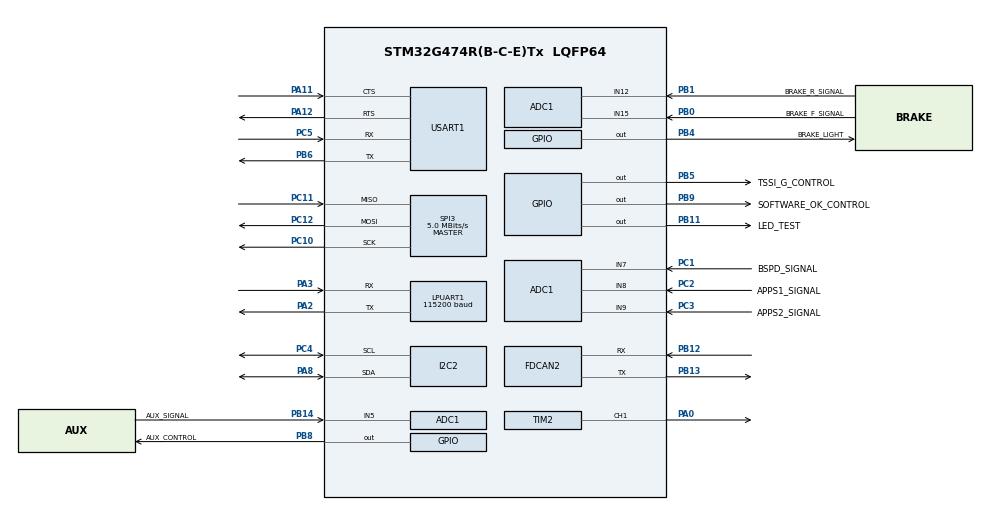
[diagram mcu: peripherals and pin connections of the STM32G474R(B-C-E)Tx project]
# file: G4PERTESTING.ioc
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ADC1.Channel-2\#ChannelRegularConversion=ADC_CHANNEL_5
ADC1.Channel-3\#ChannelRegularConversion=ADC_CHANNEL_7
ADC1.Channel-4\#ChannelRegularConversion=ADC_CHANNEL_8
ADC1.Channel-5\#ChannelRegularConversion=ADC_CHANNEL_9
ADC1.Channel-6\#ChannelRegularConversion=ADC_CHANNEL_12
ADC1.Channel-7\#ChannelRegularConversion=ADC_CHANNEL_15
ADC1.ClockPrescaler=ADC_CLOCK_ASYNC_DIV256
ADC1.ContinuousConvMode=ENABLE
ADC1.DMAContinuousRequests=ENABLE
ADC1.EOCSelection=ADC_EOC_SEQ_CONV
ADC1.ExternalTrigConv=ADC_SOFTWARE_START
ADC1.NbrOfConversion=6
ADC1.NbrOfConversionFlag=1
ADC1.OffsetNumber-2\#ChannelRegularConversion=ADC_OFFSET_NONE
ADC1.OffsetNumber-3\#ChannelRegularConversion=ADC_OFFSET_NONE
ADC1.OffsetNumber-4\#ChannelRegularConversion=ADC_OFFSET_NONE
ADC1.OffsetNumber-5\#ChannelRegularConversion=ADC_OFFSET_NONE
ADC1.OffsetNumber-6\#ChannelRegularConversion=ADC_OFFSET_NONE
ADC1.OffsetNumber-7\#ChannelRegularConversion=ADC_OFFSET_NONE
ADC1.Rank-2\#ChannelRegularConversion=1
ADC1.Rank-3\#ChannelRegularConversion=2
ADC1.Rank-4\#ChannelRegularConversion=3
ADC1.Rank-5\#ChannelRegularConversion=4
ADC1.Rank-6\#ChannelRegularConversion=5
ADC1.Rank-7\#ChannelRegularConversion=6
ADC1.SamplingTime-2\#ChannelRegularConversion=ADC_SAMPLETIME_92CYCLES_5
ADC1.SamplingTime-3\#ChannelRegularConversion=ADC_SAMPLETIME_92CYCLES_5
ADC1.SamplingTime-4\#ChannelRegularConversion=ADC_SAMPLETIME_92CYCLES_5
ADC1.SamplingTime-5\#ChannelRegularConversion=ADC_SAMPLETIME_92CYCLES_5
ADC1.SamplingTime-6\#ChannelRegularConversion=ADC_SAMPLETIME_92CYCLES_5
ADC1.SamplingTime-7\#ChannelRegularConversion=ADC_SAMPLETIME_92CYCLES_5
ADC1.master=1
Dma.ADC1.0.Direction=DMA_PERIPH_TO_MEMORY
Dma.ADC1.0.EventEnable=DISABLE
Dma.ADC1.0.Instance=DMA1_Channel1
Dma.ADC1.0.MemDataAlignment=DMA_MDATAALIGN_HALFWORD
Dma.ADC1.0.MemInc=DMA_MINC_ENABLE
Dma.ADC1.0.Mode=DMA_CIRCULAR
Dma.ADC1.0.PeriphDataAlignment=DMA_PDATAALIGN_HALFWORD
Dma.ADC1.0.PeriphInc=DMA_PINC_DISABLE
Dma.ADC1.0.Polarity=HAL_DMAMUX_REQ_GEN_RISING
Dma.ADC1.0.Priority=DMA_PRIORITY_LOW
Dma.ADC1.0.RequestNumber=1
Dma.ADC1.0.SignalID=NONE
Dma.ADC1.0.SyncEnable=DISABLE
Dma.ADC1.0.SyncPolarity=HAL_DMAMUX_SYNC_NO_EVENT
Dma.ADC1.0.SyncRequestNumber=1
Dma.ADC1.0.SyncSignalID=NONE
Dma.Request0=ADC1
FDCAN2.AutoRetransmission=ENABLE
FDCAN2.CalculateBaudRateNominal=1000000
FDCAN2.CalculateTimeBitNominal=1000
FDCAN2.CalculateTimeQuantumNominal=6.25
FDCAN2.DataPrescaler=8
FDCAN2.DataSyncJumpWidth=16
FDCAN2.DataTimeSeg1=14
FDCAN2.DataTimeSeg2=5
FDCAN2.ExtFiltersNbr=2
FDCAN2.FrameFormat=FDCAN_FRAME_CLASSIC
FDCAN2.NominalPrescaler=1
FDCAN2.NominalSyncJumpWidth=16
FDCAN2.NominalTimeSeg1=119
FDCAN2.NominalTimeSeg2=40
FDCAN2.ProtocolException=ENABLE
FDCAN2.StdFiltersNbr=0
FDCAN2.TransmitPause=DISABLE
I2C2.Timing=0x30D29DE4
LPUART1.BaudRate=115200
Mcu.Family=STM32G4
Mcu.Name=STM32G474R(B-C-E)Tx
Mcu.Package=LQFP64
NVIC.FDCAN2_IT0_IRQn=true\:0\:0\:false\:false\:true\:true\:true\:true
NVIC.PriorityGroup=NVIC_PRIORITYGROUP_4
PA0.Signal=S_TIM2_CH1
PA11.Mode=CTS_RTS
PA11.Signal=USART1_CTS
PA12.Mode=CTS_RTS
PA12.Signal=USART1_RTS
PA13.Mode=Trace_Asynchronous_SW
PA13.Signal=SYS_JTMS-SWDIO
PA14.Mode=Trace_Asynchronous_SW
PA14.Signal=SYS_JTCK-SWCLK
PA2.GPIO_Speed=GPIO_SPEED_FREQ_HIGH
PA2.Mode=Asynchronous
PA2.Signal=LPUART1_TX
PA3.GPIO_Speed=GPIO_SPEED_FREQ_HIGH
PA3.Mode=Asynchronous
PA3.Signal=LPUART1_RX
PA5.GPIO_Label=BSPD_SENSE
PA5.Signal=ADC2_IN13
PA6.GPIO_Label=IMD_SENSE
PA6.Signal=ADC2_IN3
PA7.GPIO_Label=AMS_SENSE
PA7.Signal=ADC2_IN4
PA8.Mode=I2C
PA8.Signal=I2C2_SDA
PB0.GPIO_Label=BRAKE_F_SIGNAL
PB0.Mode=IN15-Single-Ended
PB0.Signal=ADC1_IN15
PB1.GPIO_Label=BRAKE_R_SIGNAL
PB1.Mode=IN12-Single-Ended
PB1.Signal=ADC1_IN12
PB11.GPIO_Label=LED_TEST
PB11.Signal=GPIO_Output
PB12.GPIO_PuPd=GPIO_PULLUP
PB12.GPIO_Speed=GPIO_SPEED_FREQ_VERY_HIGH
PB12.Mode=FDCAN_Activate
PB12.Signal=FDCAN2_RX
PB13.GPIO_Speed=GPIO_SPEED_FREQ_VERY_HIGH
PB13.Mode=FDCAN_Activate
PB13.Signal=FDCAN2_TX
PB14.GPIO_Label=AUX_SIGNAL
PB14.Mode=IN5-Single-Ended
PB14.Signal=ADC1_IN5
PB15.GPIO_Label=STEERING_ANGLE
PB15.Signal=ADC2_IN15
PB3.Mode=Trace_Asynchronous_SW
PB3.Signal=SYS_JTDO-SWO
PB4.GPIO_Label=BRAKE_LIGHT
PB4.Signal=GPIO_Output
PB5.GPIO_Label=TSSI_G_CONTROL
PB5.Signal=GPIO_Output
PB6.Mode=Asynchronous
PB6.Signal=USART1_TX
PB7.Signal=UART4_CTS
PB8-BOOT0.GPIO_Label=AUX_CONTROL
PB8-BOOT0.Signal=GPIO_Output
PB9.GPIO_Label=SOFTWARE_OK_CONTROL
PB9.Signal=GPIO_Output
PC1.GPIO_Label=BSPD_SIGNAL
PC1.Mode=IN7-Single-Ended
PC1.Signal=ADC1_IN7
PC10.Mode=Full_Duplex_Master
PC10.Signal=SPI3_SCK
PC11.Mode=Full_Duplex_Master
PC11.Signal=SPI3_MISO
PC12.Mode=Full_Duplex_Master
PC12.Signal=SPI3_MOSI
PC2.GPIO_Label=APPS1_SIGNAL
PC2.Mode=IN8-Single-Ended
PC2.Signal=ADC1_IN8
PC3.GPIO_Label=APPS2_SIGNAL
PC3.Mode=IN9-Single-Ended
PC3.Signal=ADC1_IN9
PC4.Mode=I2C
PC4.Signal=I2C2_SCL
PC5.Mode=Asynchronous
PC5.Signal=USART1_RX
PF0-OSC_IN.Mode=HSE-External-Oscillator
PF0-OSC_IN.Signal=RCC_OSC_IN
PF1-OSC_OUT.Mode=HSE-External-Oscillator
PF1-OSC_OUT.Signal=RCC_OSC_OUT
ProjectManager.HeapSize=0x200
ProjectManager.StackSize=0x400
ProjectManager.TargetToolchain=CMake
RCC.ADC12Freq_Value=160000000
RCC.ADC345Freq_Value=160000000
RCC.AHBFreq_Value=160000000
RCC.APB1Freq_Value=160000000
RCC.APB1TimFreq_Value=160000000
RCC.APB2Freq_Value=160000000
RCC.APB2TimFreq_Value=160000000
RCC.CortexFreq_Value=160000000
RCC.EXTERNAL_CLOCK_VALUE=12288000
RCC.EnbaleCSS=true
RCC.HCLKFreq_Value=160000000
RCC.HSE_VALUE=16000000
RCC.HSI48_VALUE=48000000
RCC.HSI_VALUE=16000000
RCC.LSE_VALUE=32768
RCC.PLLN=20
RCC.PLLSourceVirtual=RCC_PLLSOURCE_HSE
RCC.SYSCLKFreq_VALUE=160000000
RCC.SYSCLKSource=RCC_SYSCLKSOURCE_PLLCLK
RCC.USBFreq_Value=160000000
RCC.VCOOutputFreq_Value=320000000
SH.S_TIM2_CH1.0=TIM2_CH1,Forced Output1 CH1
SPI3.BaudRatePrescaler=SPI_BAUDRATEPRESCALER_32
SPI3.CalculateBaudRate=5.0 MBits/s
SPI3.Direction=SPI_DIRECTION_2LINES
SPI3.Mode=SPI_MODE_MASTER
SPI3.VirtualType=VM_MASTER
TIM2.Channel-Forced\ Output1\ CH1=TIM_CHANNEL_1
USART1.VirtualMode-Asynchronous=VM_ASYNC
VP_SYS_VS_DBSignals.Mode=DisableDeadBatterySignals
VP_TIM2_VS_ClockSourceINT.Mode=Internal
board=custom

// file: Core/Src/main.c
/* USER CODE BEGIN Header */
/**
 ******************************************************************************
 * @file           : main.c
 * @brief          : Main program body
 ******************************************************************************
 * @attention
 *
 * Copyright (c) 2024 STMicroelectronics.
 * All rights reserved.
 *
 * This software is licensed under terms that can be found in the LICENSE file
 * in the root directory of this software component.
 * If no LICENSE file comes with this software, it is provided AS-IS.
 *
 ******************************************************************************
 */
/* USER CODE END Header */
#include "main.h"

#include "adc.h"
#include "dma.h"
#include "fdcan.h"
#include "gpio.h"
#include "i2c.h"
#include "spi.h"
#include "tim.h"
#include "usart.h"

void SystemClock_Config(void);

int main(void)
{

	/* MCU
	 * Configuration--------------------------------------------------------*/

	/* Reset of all peripherals, Initializes the Flash interface and the
	 * Systick. */
	HAL_Init();

	/* Configure the system clock */
	SystemClock_Config();

	/* Initialize all configured peripherals */
	MX_GPIO_Init();
	MX_DMA_Init();
	MX_FDCAN2_Init();
	MX_ADC1_Init();
	MX_LPUART1_UART_Init();
	MX_I2C2_Init();
	MX_USART1_UART_Init();
	MX_SPI3_Init();
	MX_TIM2_Init();
	/* USER CODE BEGIN 2 */

	/* Initialize CAN interface */

	/* USER CODE END 2 */

	/* Infinite loop */
	while (1) {

		// BLINKY
		HAL_GPIO_WritePin(GPIOA, GPIO_PIN_5, GPIO_PIN_SET);
		HAL_Delay(1000);
		HAL_GPIO_WritePin(GPIOA, GPIO_PIN_5, GPIO_PIN_RESET);
		HAL_Delay(1000);

		/* USER CODE BEGIN 3 */
	}
}

void SystemClock_Config(void)
{
	LL_FLASH_SetLatency(LL_FLASH_LATENCY_4);
	while (LL_FLASH_GetLatency() != LL_FLASH_LATENCY_4) {}
	LL_PWR_EnableRange1BoostMode();
	LL_RCC_HSE_Enable();
	/* Wait till HSE is ready */
	while (LL_RCC_HSE_IsReady() != 1) {}

	LL_RCC_HSE_EnableCSS();
	LL_RCC_PLL_ConfigDomain_SYS(LL_RCC_PLLSOURCE_HSE, LL_RCC_PLLM_DIV_1, 20, LL_RCC_PLLR_DIV_2);
	LL_RCC_PLL_EnableDomain_SYS();
	LL_RCC_PLL_Enable();
	/* Wait till PLL is ready */
	while (LL_RCC_PLL_IsReady() != 1) {}

	LL_RCC_SetSysClkSource(LL_RCC_SYS_CLKSOURCE_PLL);
	LL_RCC_SetAHBPrescaler(LL_RCC_SYSCLK_DIV_2);
	/* Wait till System clock is ready */
	while (LL_RCC_GetSysClkSource() != LL_RCC_SYS_CLKSOURCE_STATUS_PLL) {}

	/* Insure 1us transition state at intermediate medium speed clock*/
	for (__IO uint32_t i = (170 >> 1); i != 0; i--)
		;

	/* Set AHB prescaler*/
	LL_RCC_SetAHBPrescaler(LL_RCC_SYSCLK_DIV_1);
	LL_RCC_SetAPB1Prescaler(LL_RCC_APB1_DIV_1);
	LL_RCC_SetAPB2Prescaler(LL_RCC_APB2_DIV_1);
	LL_SetSystemCoreClock(160000000);

	/* Update the time base */
	if (HAL_InitTick(TICK_INT_PRIORITY) != HAL_OK) {
		Error_Handler();
	}
}

void Error_Handler(void)
{
	/* USER CODE BEGIN Error_Handler_Debug */
	/* User can add his own implementation to report the HAL error return
	 * state */
	__disable_irq();
	while (1) {}
	/* USER CODE END Error_Handler_Debug */
}
#ifdef USE_FULL_ASSERT
/**
 * @brief  Reports the name of the source file and the source line number
 *         where the assert_param error has occurred.
 * @param  file: pointer to the source file name
 * @param  line: assert_param error line source number
 * @retval None
 */
void assert_failed(uint8_t *file, uint32_t line)
{
	/* USER CODE BEGIN 6 */
	/* User can add his own implementation to report the file name and line
	   number, ex: printf("Wrong parameters value: file %s on line %d\r\n",
	   file, line) */
	/* USER CODE END 6 */
}
#endif /* USE_FULL_ASSERT */
